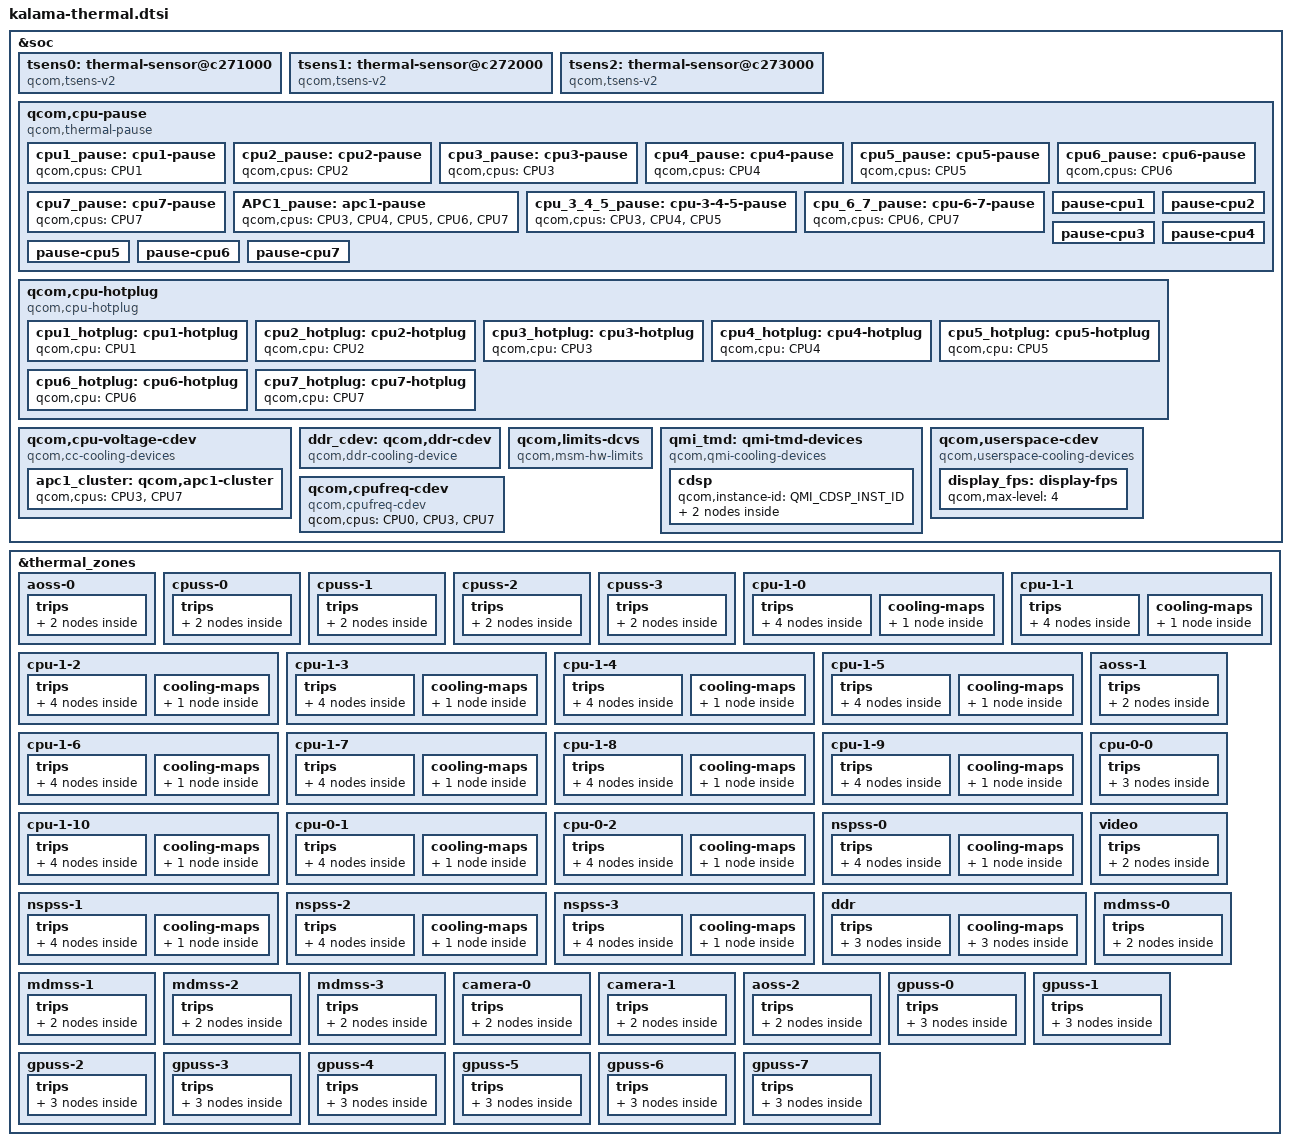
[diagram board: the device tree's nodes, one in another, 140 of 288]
#include <dt-bindings/thermal/thermal_qti.h>

&soc {
	tsens0: thermal-sensor@c271000 {
		compatible = "qcom,tsens-v2";
		reg = <0x0c271000 0x1ff>, /* TM */
			<0x0c222000 0x1ff>; /* SROT */
		#qcom,sensors = <16>;
		interrupts = <GIC_SPI 506 IRQ_TYPE_LEVEL_HIGH>,
			     <GIC_SPI 640 IRQ_TYPE_LEVEL_HIGH>;
		interrupt-names = "uplow","critical";
		#thermal-sensor-cells = <1>;
	};

	tsens1: thermal-sensor@c272000 {
		compatible = "qcom,tsens-v2";
		reg = <0x0c272000 0x1ff>, /* TM */
			<0x0c223000 0x1ff>; /* SROT */
		#qcom,sensors = <16>;
		interrupts = <GIC_SPI 507 IRQ_TYPE_LEVEL_HIGH>,
			     <GIC_SPI 641 IRQ_TYPE_LEVEL_HIGH>;
		interrupt-names = "uplow","critical";
		#thermal-sensor-cells = <1>;
	};

	tsens2: thermal-sensor@c273000 {
		compatible = "qcom,tsens-v2";
		reg = <0x0c273000 0x1ff>, /* TM */
			<0x0c224000 0x1ff>; /* SROT */
		#qcom,sensors = <9>;
		interrupts = <GIC_SPI 508 IRQ_TYPE_LEVEL_HIGH>,
			     <GIC_SPI 642 IRQ_TYPE_LEVEL_HIGH>;
		interrupt-names = "uplow","critical";
		#thermal-sensor-cells = <1>;
	};

	qcom,cpu-pause {
		compatible = "qcom,thermal-pause";

		cpu1_pause: cpu1-pause {
			qcom,cpus = <&CPU1>;
			#cooling-cells = <2>;
		};

		cpu2_pause: cpu2-pause {
			qcom,cpus = <&CPU2>;
			#cooling-cells = <2>;
		};

		cpu3_pause: cpu3-pause {
			qcom,cpus = <&CPU3>;
			#cooling-cells = <2>;
		};

		cpu4_pause: cpu4-pause {
			qcom,cpus = <&CPU4>;
			#cooling-cells = <2>;
		};

		cpu5_pause: cpu5-pause {
			qcom,cpus = <&CPU5>;
			#cooling-cells = <2>;
		};

		cpu6_pause: cpu6-pause {
			qcom,cpus = <&CPU6>;
			#cooling-cells = <2>;
		};

		cpu7_pause: cpu7-pause {
			qcom,cpus = <&CPU7>;
			#cooling-cells = <2>;
		};

		APC1_pause: apc1-pause {
			qcom,cpus = <&CPU3 &CPU4 &CPU5 &CPU6 &CPU7>;
			#cooling-cells = <2>;
		};

		cpu_3_4_5_pause: cpu-3-4-5-pause {
			qcom,cpus = <&CPU3 &CPU4 &CPU5>;
			#cooling-cells = <2>;
		};

		cpu_6_7_pause: cpu-6-7-pause {
			qcom,cpus = <&CPU6 &CPU7>;
			#cooling-cells = <2>;
		};

		/* Thermal-engine cooling devices */
		pause-cpu1 {
			qcom,cpus = <&CPU1>;
			qcom,cdev-alias = "pause-cpu1";
		};

		pause-cpu2 {
			qcom,cpus = <&CPU2>;
			qcom,cdev-alias = "pause-cpu2";
		};

		pause-cpu3 {
			qcom,cpus = <&CPU3>;
			qcom,cdev-alias = "pause-cpu3";
		};

		pause-cpu4 {
			qcom,cpus = <&CPU4>;
			qcom,cdev-alias = "pause-cpu4";
		};

		pause-cpu5 {
			qcom,cpus = <&CPU5>;
			qcom,cdev-alias = "pause-cpu5";
		};

		pause-cpu6 {
			qcom,cpus = <&CPU6>;
			qcom,cdev-alias = "pause-cpu6";
		};

		pause-cpu7 {
			qcom,cpus = <&CPU7>;
			qcom,cdev-alias = "pause-cpu7";
		};
	};

	qcom,cpu-hotplug {
		compatible = "qcom,cpu-hotplug";

		cpu1_hotplug: cpu1-hotplug {
			qcom,cpu = <&CPU1>;
			#cooling-cells = <2>;
		};

		cpu2_hotplug: cpu2-hotplug {
			qcom,cpu = <&CPU2>;
			#cooling-cells = <2>;
		};

		cpu3_hotplug: cpu3-hotplug {
			qcom,cpu = <&CPU3>;
			#cooling-cells = <2>;
		};

		cpu4_hotplug: cpu4-hotplug {
			qcom,cpu = <&CPU4>;
			#cooling-cells = <2>;
		};

		cpu5_hotplug: cpu5-hotplug {
			qcom,cpu = <&CPU5>;
			#cooling-cells = <2>;
		};

		cpu6_hotplug: cpu6-hotplug {
			qcom,cpu = <&CPU6>;
			#cooling-cells = <2>;
		};

		cpu7_hotplug: cpu7-hotplug {
			qcom,cpu = <&CPU7>;
			#cooling-cells = <2>;
		};
	};

	qcom,cpu-voltage-cdev {
		compatible = "qcom,cc-cooling-devices";
		apc1_cluster: qcom,apc1-cluster {
			qcom,cpus = <&CPU3 &CPU7>;
			#cooling-cells = <2>;
		};
	};

	ddr_cdev: qcom,ddr-cdev {
		compatible = "qcom,ddr-cooling-device";
		#cooling-cells = <2>;
		qcom,bus-width = <4>;
		qcom,freq-table =
			< 547000 >,
			< 768000 >,
			< 1555200 >,
			< 1708800 >,
			< 2092800 >,
			< 2736000 >,
			< 3196800 >,
			< 3744000 >,
			< 4262400 >;
		interconnects = <&mc_virt MASTER_LLCC &mc_virt SLAVE_EBI1>;
	};

	qcom,limits-dcvs {
		compatible = "qcom,msm-hw-limits";
		isens_vref_0p8-supply = <&pm_v6e_l1_ao>;
		isens-vref-0p8-settings = <880000 880000 30000>;
		isens_vref_1p8-supply = <&pm_v6e_l3_ao>;
		isens-vref-1p8-settings = <1200000 1200000 8000>;
	};

	qmi_tmd: qmi-tmd-devices {
		compatible = "qcom,qmi-cooling-devices";
		cdsp {
			qcom,instance-id = <QMI_CDSP_INST_ID>;

			cdsp_sw: cdsp_kr {
				qcom,qmi-dev-name = "cdsp_sw";
				#cooling-cells = <2>;
			};

			cdsp_hw: cdsp_hw {
				qcom,qmi-dev-name = "cdsp_hw";
				#cooling-cells = <2>;
			};
		};
	};

	qcom,userspace-cdev {
		compatible = "qcom,userspace-cooling-devices";

		display_fps: display-fps {
			qcom,max-level = <4>;
			#cooling-cells = <2>;
		};
	};

	qcom,cpufreq-cdev {
		compatible = "qcom,cpufreq-cdev";
		qcom,cpus = <&CPU0 &CPU3 &CPU7>;
	};
};

#include "kalama-thermal-modem.dtsi"

&thermal_zones {
	aoss-0 {
		polling-delay-passive = <0>;
		polling-delay = <0>;
		thermal-sensors = <&tsens0 0>;
		trips {
			thermal-engine-config {
				temperature = <125000>;
				hysteresis = <1000>;
				type = "passive";
			};

			reset-mon-cfg {
				temperature = <115000>;
				hysteresis = <5000>;
				type = "passive";
			};
		};
	};

	cpuss-0 {
		polling-delay-passive = <0>;
		polling-delay = <0>;
		thermal-sensors = <&tsens0 1>;
		trips {
			thermal-engine-config {
				temperature = <125000>;
				hysteresis = <1000>;
				type = "passive";
			};

			reset-mon-cfg {
				temperature = <115000>;
				hysteresis = <5000>;
				type = "passive";
			};
		};
	};

	cpuss-1 {
		polling-delay-passive = <0>;
		polling-delay = <0>;
		thermal-sensors = <&tsens0 2>;
		trips {
			thermal-engine-config {
				temperature = <125000>;
				hysteresis = <1000>;
				type = "passive";
			};

			reset-mon-cfg {
				temperature = <115000>;
				hysteresis = <5000>;
				type = "passive";
			};
		};
	};

	cpuss-2 {
		polling-delay-passive = <0>;
		polling-delay = <0>;
		thermal-sensors = <&tsens0 3>;
		trips {
			thermal-engine-config {
				temperature = <125000>;
				hysteresis = <1000>;
				type = "passive";
			};

			reset-mon-cfg {
				temperature = <115000>;
				hysteresis = <5000>;
				type = "passive";
			};
		};
	};

	cpuss-3 {
		polling-delay-passive = <0>;
		polling-delay = <0>;
		thermal-sensors = <&tsens0 4>;
		trips {
			thermal-engine-config {
				temperature = <125000>;
				hysteresis = <1000>;
				type = "passive";
			};

			reset-mon-cfg {
				temperature = <115000>;
				hysteresis = <5000>;
				type = "passive";
			};
		};
	};

	cpu-1-0 {
		polling-delay-passive = <0>;
		polling-delay = <0>;
		thermal-sensors = <&tsens0 5>;
		trips {
			thermal-engine-config {
				temperature = <125000>;
				hysteresis = <1000>;
				type = "passive";
			};

			thermal-hal-config {
				temperature = <125000>;
				hysteresis = <1000>;
				type = "passive";
			};

			cpu3_emerg0: cpu3-emerg0-cfg {
				temperature = <110000>;
				hysteresis = <10000>;
				type = "passive";
			};

			reset-mon-cfg {
				temperature = <115000>;
				hysteresis = <5000>;
				type = "passive";
			};
		};

		cooling-maps {
			cpu10_cdev {
				trip = <&cpu3_emerg0>;
				cooling-device = <&cpu3_pause 1 1>;
			};
		};
	};

	cpu-1-1 {
		polling-delay-passive = <0>;
		polling-delay = <0>;
		thermal-sensors = <&tsens0 6>;
		trips {
			thermal-engine-config {
				temperature = <125000>;
				hysteresis = <1000>;
				type = "passive";
			};

			thermal-hal-config {
				temperature = <125000>;
				hysteresis = <1000>;
				type = "passive";
			};

			cpu3_emerg1: cpu3-emerg1-cfg {
				temperature = <110000>;
				hysteresis = <10000>;
				type = "passive";
			};

			reset-mon-cfg {
				temperature = <115000>;
				hysteresis = <5000>;
				type = "passive";
			};
		};

		cooling-maps {
			cpu11_cdev {
				trip = <&cpu3_emerg1>;
				cooling-device = <&cpu3_pause 1 1>;
			};
		};
	};

	cpu-1-2 {
		polling-delay-passive = <10>;
		polling-delay = <0>;
		thermal-sensors = <&tsens0 7>;
		trips {
			thermal-engine-config {
				temperature = <125000>;
				hysteresis = <1000>;
				type = "passive";
			};

			thermal-hal-config {
				temperature = <125000>;
				hysteresis = <1000>;
				type = "passive";
			};

			cpu4_emerg0: cpu4-emerg0-cfg {
				temperature = <110000>;
				hysteresis = <10000>;
				type = "passive";
			};

			reset-mon-cfg {
				temperature = <115000>;
				hysteresis = <5000>;
				type = "passive";
			};
		};

		cooling-maps {
			cpu12_cdev {
				trip = <&cpu4_emerg0>;
				cooling-device = <&cpu4_pause 1 1>;
			};
		};
	};

	cpu-1-3 {
		polling-delay-passive = <10>;
		polling-delay = <0>;
		thermal-sensors = <&tsens0 8>;
		trips {
			thermal-engine-config {
				temperature = <125000>;
				hysteresis = <1000>;
				type = "passive";
			};

			thermal-hal-config {
				temperature = <125000>;
				hysteresis = <1000>;
				type = "passive";
			};

			cpu4_emerg1: cpu4-emerg1-cfg {
				temperature = <110000>;
				hysteresis = <10000>;
				type = "passive";
			};

			reset-mon-cfg {
				temperature = <115000>;
				hysteresis = <5000>;
				type = "passive";
			};
		};

		cooling-maps {
			cpu13_cdev {
				trip = <&cpu4_emerg1>;
				cooling-device = <&cpu4_pause 1 1>;
			};
		};
	};

	cpu-1-4 {
		polling-delay-passive = <10>;
		polling-delay = <0>;
		thermal-sensors = <&tsens0 9>;
		trips {
			thermal-engine-config {
				temperature = <125000>;
				hysteresis = <1000>;
				type = "passive";
			};

			thermal-hal-config {
				temperature = <125000>;
				hysteresis = <1000>;
				type = "passive";
			};

			cpu5_emerg0: cpu5-emerg0-cfg {
				temperature = <110000>;
				hysteresis = <10000>;
				type = "passive";
			};

			reset-mon-cfg {
				temperature = <115000>;
				hysteresis = <5000>;
				type = "passive";
			};
		};

		cooling-maps {
			cpu14_cdev {
				trip = <&cpu5_emerg0>;
				cooling-device = <&cpu5_pause 1 1>;
			};
		};
	};

	cpu-1-5 {
		polling-delay-passive = <10>;
		polling-delay = <0>;
		thermal-sensors = <&tsens0 10>;
		trips {
			thermal-engine-config {
				temperature = <125000>;
				hysteresis = <1000>;
				type = "passive";
			};

			thermal-hal-config {
				temperature = <125000>;
				hysteresis = <1000>;
				type = "passive";
			};

			cpu5_emerg1: cpu5-emerg1-cfg {
				temperature = <110000>;
				hysteresis = <10000>;
				type = "passive";
			};

			reset-mon-cfg {
				temperature = <115000>;
				hysteresis = <5000>;
				type = "passive";
			};
		};

		cooling-maps {
			cpu15_cdev {
				trip = <&cpu5_emerg1>;
				cooling-device = <&cpu5_pause 1 1>;
			};
		};
	};

	cpu-1-6 {
		polling-delay-passive = <10>;
		polling-delay = <0>;
		thermal-sensors = <&tsens0 11>;
		trips {
			thermal-engine-config {
				temperature = <125000>;
				hysteresis = <1000>;
				type = "passive";
			};

			thermal-hal-config {
				temperature = <125000>;
				hysteresis = <1000>;
				type = "passive";
			};

			cpu6_emerg0: cpu6-emerg0-cfg {
				temperature = <110000>;
				hysteresis = <10000>;
				type = "passive";
			};

			reset-mon-cfg {
				temperature = <115000>;
				hysteresis = <5000>;
				type = "passive";
			};
		};

		cooling-maps {
			cpu16_cdev {
				trip = <&cpu6_emerg0>;
				cooling-device = <&cpu6_pause 1 1>;
			};
		};
	};

	cpu-1-7 {
		polling-delay-passive = <10>;
		polling-delay = <0>;
		thermal-sensors = <&tsens0 12>;
		trips {
			thermal-engine-config {
				temperature = <125000>;
				hysteresis = <1000>;
				type = "passive";
			};

			thermal-hal-config {
				temperature = <125000>;
				hysteresis = <1000>;
				type = "passive";
			};

			cpu6_emerg1: cpu6-emerg1-cfg {
				temperature = <110000>;
				hysteresis = <10000>;
				type = "passive";
			};

			reset-mon-cfg {
				temperature = <115000>;
				hysteresis = <5000>;
				type = "passive";
			};
		};

		cooling-maps {
			cpu17_cdev {
				trip = <&cpu6_emerg1>;
				cooling-device = <&cpu6_pause 1 1>;
			};
		};
	};

	cpu-1-8 {
		polling-delay-passive = <10>;
		polling-delay = <0>;
		thermal-sensors = <&tsens0 13>;
		trips {
			thermal-engine-config {
				temperature = <125000>;
				hysteresis = <1000>;
				type = "passive";
			};

			thermal-hal-config {
				temperature = <125000>;
				hysteresis = <1000>;
				type = "passive";
			};

			cpu7_emerg0: cpu7-emerg0-cfg {
				temperature = <110000>;
				hysteresis = <10000>;
				type = "passive";
			};

			reset-mon-cfg {
				temperature = <115000>;
				hysteresis = <5000>;
				type = "passive";
			};
		};

		cooling-maps {
			cpu18_cdev {
				trip = <&cpu7_emerg0>;
				cooling-device = <&cpu7_pause 1 1>;
			};
		};
	};

	cpu-1-9 {
		polling-delay-passive = <10>;
		polling-delay = <0>;
		thermal-sensors = <&tsens0 14>;
		trips {
			thermal-engine-config {
				temperature = <125000>;
				hysteresis = <1000>;
				type = "passive";
			};

			thermal-hal-config {
				temperature = <125000>;
				hysteresis = <1000>;
				type = "passive";
			};

			cpu7_emerg1: cpu7-emerg1-cfg {
				temperature = <110000>;
				hysteresis = <10000>;
				type = "passive";
			};

			reset-mon-cfg {
				temperature = <115000>;
				hysteresis = <5000>;
				type = "passive";
			};
		};

		cooling-maps {
			cpu19_cdev {
				trip = <&cpu7_emerg1>;
				cooling-device = <&cpu7_pause 1 1>;
			};
		};
	};

	cpu-1-10 {
		polling-delay-passive = <10>;
		polling-delay = <0>;
		thermal-sensors = <&tsens0 15>;
		trips {
			thermal-engine-config {
				temperature = <125000>;
				hysteresis = <1000>;
				type = "passive";
			};

			thermal-hal-config {
				temperature = <125000>;
				hysteresis = <1000>;
				type = "passive";
			};

			cpu7_emerg2: cpu7-emerg2-cfg {
				temperature = <110000>;
				hysteresis = <10000>;
				type = "passive";
			};

			reset-mon-cfg {
				temperature = <115000>;
				hysteresis = <5000>;
				type = "passive";
			};
		};

		cooling-maps {
			cpu110_cdev {
				trip = <&cpu7_emerg2>;
				cooling-device = <&cpu7_pause 1 1>;
			};
		};
	};

	aoss-1 {
		polling-delay-passive = <0>;
		polling-delay = <0>;
		thermal-sensors = <&tsens1 0>;
		trips {
			thermal-engine-config {
				temperature = <125000>;
				hysteresis = <1000>;
				type = "passive";
			};

			reset-mon-cfg {
				temperature = <115000>;
				hysteresis = <5000>;
				type = "passive";
			};
		};
	};

	cpu-0-0 {
		polling-delay-passive = <0>;
		polling-delay = <0>;
		thermal-sensors = <&tsens1 1>;
		trips {
			thermal-engine-config {
				temperature = <125000>;
				hysteresis = <1000>;
				type = "passive";
			};

			thermal-hal-config {
				temperature = <125000>;
				hysteresis = <1000>;
				type = "passive";
			};

			reset-mon-cfg {
				temperature = <115000>;
				hysteresis = <5000>;
				type = "passive";
			};
		};
	};

	cpu-0-1 {
		polling-delay-passive = <0>;
		polling-delay = <0>;
		thermal-sensors = <&tsens1 2>;
		trips {
			thermal-engine-config {
				temperature = <125000>;
				hysteresis = <1000>;
				type = "passive";
			};

			thermal-hal-config {
				temperature = <125000>;
				hysteresis = <1000>;
				type = "passive";
			};

			cpu1_emerg: cpu1-emerg-cfg {
				temperature = <110000>;
				hysteresis = <10000>;
				type = "passive";
			};

			reset-mon-cfg {
				temperature = <115000>;
				hysteresis = <5000>;
				type = "passive";
			};
		};

		cooling-maps {
			cpu01_cdev {
				trip = <&cpu1_emerg>;
				cooling-device = <&cpu1_pause 1 1>;
			};
		};
	};

	cpu-0-2 {
		polling-delay-passive = <0>;
		polling-delay = <0>;
		thermal-sensors = <&tsens1 3>;
		trips {
			thermal-engine-config {
				temperature = <125000>;
				hysteresis = <1000>;
				type = "passive";
			};

			thermal-hal-config {
				temperature = <125000>;
				hysteresis = <1000>;
				type = "passive";
			};

			cpu2_emerg: cpu2-emerg-cfg {
				temperature = <110000>;
				hysteresis = <10000>;
				type = "passive";
			};

			reset-mon-cfg {
				temperature = <115000>;
				hysteresis = <5000>;
				type = "passive";
			};
		};

		cooling-maps {
			cpu02_cdev {
				trip = <&cpu2_emerg>;
				cooling-device = <&cpu2_pause 1 1>;
			};
		};
	};

	nspss-0 {
		polling-delay-passive = <10>;
		polling-delay = <0>;
		thermal-sensors = <&tsens1 4>;
		trips {
			thermal-engine-config {
				temperature = <125000>;
				hysteresis = <1000>;
				type = "passive";
			};

			thermal-hal-config {
				temperature = <125000>;
				hysteresis = <1000>;
				type = "passive";
			};

			nspss_0_config: junction-config {
				temperature = <95000>;
				hysteresis = <5000>;
				type = "passive";
			};

			reset-mon-cfg {
				temperature = <115000>;
				hysteresis = <5000>;
				type = "passive";
			};
		};

		cooling-maps {
			nsp_cdev {
				trip = <&nspss_0_config>;
				cooling-device = <&cdsp_sw THERMAL_NO_LIMIT
							THERMAL_NO_LIMIT>;
			};
		};
	};

	nspss-1 {
		polling-delay-passive = <10>;
		polling-delay = <0>;
		thermal-sensors = <&tsens1 5>;
		trips {
			thermal-engine-config {
				temperature = <125000>;
				hysteresis = <1000>;
				type = "passive";
			};

			thermal-hal-config {
				temperature = <125000>;
				hysteresis = <1000>;
				type = "passive";
			};

			nspss_1_config: junction-config {
				temperature = <95000>;
				hysteresis = <5000>;
				type = "passive";
			};

			reset-mon-cfg {
				temperature = <115000>;
				hysteresis = <5000>;
				type = "passive";
			};
		};

		cooling-maps {
			nsp_cdev {
				trip = <&nspss_1_config>;
				cooling-device = <&cdsp_sw THERMAL_NO_LIMIT
							THERMAL_NO_LIMIT>;
			};
		};
	};

	nspss-2 {
		polling-delay-passive = <10>;
		polling-delay = <0>;
		thermal-sensors = <&tsens1 6>;
		trips {
			thermal-engine-config {
				temperature = <125000>;
				hysteresis = <1000>;
				type = "passive";
			};

			thermal-hal-config {
				temperature = <125000>;
				hysteresis = <1000>;
				type = "passive";
			};

			nspss_2_config: junction-config {
				temperature = <95000>;
				hysteresis = <5000>;
				type = "passive";
			};

			reset-mon-cfg {
				temperature = <115000>;
				hysteresis = <5000>;
				type = "passive";
			};
		};

		cooling-maps {
			nsp_cdev {
				trip = <&nspss_2_config>;
				cooling-device = <&cdsp_sw THERMAL_NO_LIMIT
							THERMAL_NO_LIMIT>;
			};
		};
	};

	nspss-3 {
		polling-delay-passive = <10>;
		polling-delay = <0>;
		thermal-sensors = <&tsens1 7>;
		trips {
			thermal-engine-config {
				temperature = <125000>;
				hysteresis = <1000>;
				type = "passive";
			};

			thermal-hal-config {
				temperature = <125000>;
				hysteresis = <1000>;
				type = "passive";
			};

			nspss_3_config: junction-config {
				temperature = <95000>;
				hysteresis = <5000>;
				type = "passive";
			};

			reset-mon-cfg {
				temperature = <115000>;
				hysteresis = <5000>;
				type = "passive";
			};
		};

		cooling-maps {
			nsp_cdev {
				trip = <&nspss_3_config>;
				cooling-device = <&cdsp_sw THERMAL_NO_LIMIT
							THERMAL_NO_LIMIT>;
			};
		};
	};

	video {
		polling-delay-passive = <0>;
		polling-delay = <0>;
		thermal-sensors = <&tsens1 8>;
		trips {
			thermal-engine-config {
				temperature = <125000>;
				hysteresis = <1000>;
				type = "passive";
			};

			reset-mon-cfg {
				temperature = <115000>;
				hysteresis = <5000>;
				type = "passive";
			};
		};
	};

	ddr {
		polling-delay-passive = <10>;
		polling-delay = <0>;
		thermal-sensors = <&tsens1 9>;
		trips {
			thermal-engine-config {
				temperature = <125000>;
				hysteresis = <1000>;
				type = "passive";
			};

			ddr_config0: ddr0-config {
				temperature = <90000>;
				hysteresis = <5000>;
				type = "passive";
			};

			reset-mon-cfg {
				temperature = <115000>;
				hysteresis = <5000>;
				type = "passive";
			};
		};

		cooling-maps {
			gold_cdev {
				trip = <&ddr_config0>;
				cooling-device = <&CPU3
					THERMAL_NO_LIMIT THERMAL_NO_LIMIT>;
			};

			gold_plus_cdev {
				trip = <&ddr_config0>;
				cooling-device = <&CPU7
					THERMAL_NO_LIMIT THERMAL_NO_LIMIT>;
			};

			ddr_cdev {
				trip = <&ddr_config0>;
				cooling-device = <&ddr_cdev 5 5>;
			};
		};
	};

	mdmss-0 {
		polling-delay-passive = <0>;
		polling-delay = <0>;
		thermal-sensors = <&tsens1 10>;
		trips {
			thermal-engine-config {
				temperature = <125000>;
				hysteresis = <1000>;
				type = "passive";
			};

			reset-mon-cfg {
				temperature = <115000>;
				hysteresis = <5000>;
				type = "passive";
			};
		};
	};

	mdmss-1 {
		polling-delay-passive = <0>;
		polling-delay = <0>;
		thermal-sensors = <&tsens1 11>;
		trips {
			thermal-engine-config {
				temperature = <125000>;
				hysteresis = <1000>;
				type = "passive";
			};

			reset-mon-cfg {
				temperature = <115000>;
				hysteresis = <5000>;
				type = "passive";
			};
		};
	};

	mdmss-2 {
		polling-delay-passive = <0>;
		polling-delay = <0>;
		thermal-sensors = <&tsens1 12>;
		trips {
			thermal-engine-config {
				temperature = <125000>;
				hysteresis = <1000>;
				type = "passive";
			};

			reset-mon-cfg {
				temperature = <115000>;
				hysteresis = <5000>;
				type = "passive";
			};
		};
	};

	mdmss-3 {
		polling-delay-passive = <0>;
		polling-delay = <0>;
		thermal-sensors = <&tsens1 13>;
		trips {
			thermal-engine-config {
				temperature = <125000>;
				hysteresis = <1000>;
				type = "passive";
			};

			reset-mon-cfg {
				temperature = <115000>;
				hysteresis = <5000>;
				type = "passive";
			};
		};
	};

	camera-0 {
		polling-delay-passive = <0>;
		polling-delay = <0>;
		thermal-sensors = <&tsens1 14>;
		trips {
			thermal-engine-config {
				temperature = <125000>;
				hysteresis = <1000>;
				type = "passive";
			};

			reset-mon-cfg {
				temperature = <115000>;
				hysteresis = <5000>;
				type = "passive";
			};
		};
	};

	camera-1 {
		polling-delay-passive = <0>;
		polling-delay = <0>;
		thermal-sensors = <&tsens1 15>;
		trips {
			thermal-engine-config {
				temperature = <125000>;
				hysteresis = <1000>;
				type = "passive";
			};

			reset-mon-cfg {
				temperature = <115000>;
				hysteresis = <5000>;
				type = "passive";
			};
		};
	};

	aoss-2 {
		polling-delay-passive = <0>;
		polling-delay = <0>;
		thermal-sensors = <&tsens2 0>;
		trips {
			thermal-engine-config {
				temperature = <125000>;
				hysteresis = <1000>;
				type = "passive";
			};

			reset-mon-cfg {
				temperature = <115000>;
				hysteresis = <5000>;
				type = "passive";
			};
		};
	};

	gpuss-0 {
		polling-delay-passive = <0>;
		polling-delay = <0>;
		thermal-sensors = <&tsens2 1>;
		trips {
			thermal-engine-config {
				temperature = <125000>;
				hysteresis = <1000>;
				type = "passive";
			};

			thermal-hal-config {
				temperature = <125000>;
				hysteresis = <1000>;
				type = "passive";
			};

			reset-mon-cfg {
				temperature = <115000>;
				hysteresis = <5000>;
				type = "passive";
			};
		};
	};

	gpuss-1 {
		polling-delay-passive = <0>;
		polling-delay = <0>;
		thermal-sensors = <&tsens2 2>;
		trips {
			thermal-engine-config {
				temperature = <125000>;
				hysteresis = <1000>;
				type = "passive";
			};

			thermal-hal-config {
				temperature = <125000>;
				hysteresis = <1000>;
				type = "passive";
			};

			reset-mon-cfg {
				temperature = <115000>;
				hysteresis = <5000>;
				type = "passive";
			};
		};
	};

	gpuss-2 {
		polling-delay-passive = <0>;
		polling-delay = <0>;
		thermal-sensors = <&tsens2 3>;
		trips {
			thermal-engine-config {
				temperature = <125000>;
				hysteresis = <1000>;
				type = "passive";
			};

			thermal-hal-config {
				temperature = <125000>;
				hysteresis = <1000>;
				type = "passive";
			};

			reset-mon-cfg {
				temperature = <115000>;
				hysteresis = <5000>;
				type = "passive";
			};
		};
	};

	gpuss-3 {
		polling-delay-passive = <0>;
		polling-delay = <0>;
		thermal-sensors = <&tsens2 4>;
		trips {
			thermal-engine-config {
				temperature = <125000>;
				hysteresis = <1000>;
				type = "passive";
			};

			thermal-hal-config {
				temperature = <125000>;
				hysteresis = <1000>;
				type = "passive";
			};

			reset-mon-cfg {
				temperature = <115000>;
				hysteresis = <5000>;
				type = "passive";
			};
		};
	};

	gpuss-4 {
		polling-delay-passive = <0>;
		polling-delay = <0>;
		thermal-sensors = <&tsens2 5>;
		trips {
			thermal-engine-config {
				temperature = <125000>;
				hysteresis = <1000>;
				type = "passive";
			};

			thermal-hal-config {
				temperature = <125000>;
				hysteresis = <1000>;
				type = "passive";
			};

			reset-mon-cfg {
				temperature = <115000>;
				hysteresis = <5000>;
				type = "passive";
			};
		};
	};

	gpuss-5 {
		polling-delay-passive = <0>;
		polling-delay = <0>;
		thermal-sensors = <&tsens2 6>;
		trips {
			thermal-engine-config {
				temperature = <125000>;
				hysteresis = <1000>;
				type = "passive";
			};

			thermal-hal-config {
				temperature = <125000>;
				hysteresis = <1000>;
				type = "passive";
			};

			reset-mon-cfg {
				temperature = <115000>;
				hysteresis = <5000>;
				type = "passive";
			};
		};
	};

	gpuss-6 {
		polling-delay-passive = <0>;
		polling-delay = <0>;
		thermal-sensors = <&tsens2 7>;
		trips {
			thermal-engine-config {
				temperature = <125000>;
				hysteresis = <1000>;
				type = "passive";
			};

			thermal-hal-config {
				temperature = <125000>;
				hysteresis = <1000>;
				type = "passive";
			};

			reset-mon-cfg {
				temperature = <115000>;
				hysteresis = <5000>;
				type = "passive";
			};
		};
	};

	gpuss-7 {
		polling-delay-passive = <0>;
		polling-delay = <0>;
		thermal-sensors = <&tsens2 8>;
		trips {
			thermal-engine-config {
				temperature = <125000>;
				hysteresis = <1000>;
				type = "passive";
			};

			thermal-hal-config {
				temperature = <125000>;
				hysteresis = <1000>;
				type = "passive";
			};

			reset-mon-cfg {
				temperature = <115000>;
				hysteresis = <5000>;
				type = "passive";
			};
		};
	};
};
